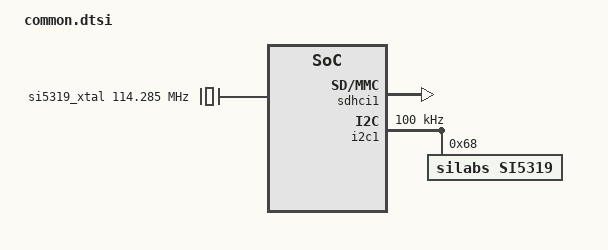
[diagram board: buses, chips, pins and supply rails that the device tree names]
/include/ "system-conf.dtsi"

// / {
// 	chosen {
// 		bootargs = "earlycon console=ttyPS0,115200 root=/dev/ram0 rw cma=256M uio_pdrv_genirq.of_id=generic-uio";
// 		stdout-path = "serial0:115200n8";
// 	};
// };

&sdhci1 {
	status = "okay";
	no-1-8-v;
	disable-wp;
};

// &watchdog0 {
// 	status = "okay";
// 	reset-on-timeout;
// 	timeout-sec = <10>;
// };

// &usb0 {
// 	status = "okay";
// };

// &dwc3_0 {
// 	status = "okay";
// 	dr_mode = "host";
// 	snps,usb3_lpm_capable;
// 	phy-names = "usb3-phy";
// 	// phys = <&lane2 PHY_TYPE_USB3 0 2 26000000>;
// 	phys = <&lane2 PHY_TYPE_USB3 0 3 26000000>;
// 	maximum-speed = "super-speed";
// };

// &usb1 {
// 	status = "okay";
// };

// &dwc3_1 {
// 	status = "okay";
// 	dr_mode = "host";
// 	snps,usb3_lpm_capable;
// 	phy-names = "usb3-phy";
// 	// phys = <&lane3 PHY_TYPE_USB3 1 3 26000000>;
// 	phys = <&lane3 PHY_TYPE_USB3 1 3 26000000>;
// 	maximum-speed = "super-speed";
// };

////////////////////////////////////////////////////////////////////////////
// system peripherals

&amba_pl {
	// si5341_xtal: si5341_xtal {
	// 	compatible = "fixed-clock";
	// 	#clock-cells = <0>;
	// 	clock-frequency = <48000000>;
	// };

	si5319_xtal: si5319_xtal {
		compatible = "fixed-clock";
		#clock-cells = <0>;
		clock-frequency = <114285000>;
	};

	// si5341_vdd_1_8: si5341_regulator@0 {
	// 	compatible = "regulator-fixed";
	// 	regulator-name = "si5341_vdd_1_8";
	// 	regulator-min-microvolt = <1800000>;
	// 	regulator-max-microvolt = <1800000>;
	// 	regulator-always-on;
	// };

	// si5341_vdd_3_3: si5341_regulator@1 {
	// 	compatible = "regulator-fixed";
	// 	regulator-name = "si5341_vdd_3_3";
	// 	regulator-min-microvolt = <3300000>;
	// 	regulator-max-microvolt = <3300000>;
	// 	regulator-always-on;
	// };
};

&i2c1 {
	clock-frequency = <100000>;

	// si5341: clock-generator@76 {
	// 	status = "okay";
	// 	reg = <0x76>;
	// 	compatible = "silabs,si5341";
	// 	#clock-cells = <2>;
	// 	#address-cells = <1>;
	// 	#size-cells = <0>;
	// 	clocks = <&si5341_xtal>;
	// 	clock-names = "xtal";

	// 	silabs,iovdd-33;
	// 	silabs,pll-m-num = <14000>; /* PLL at 14.0 GHz */
	// 	silabs,pll-m-den = <48>;
	// 	silabs,reprogram; /* Chips are not programmed, always reset */

	// 	vdd-supply = <&si5341_vdd_1_8>;
	// 	vdda-supply = <&si5341_vdd_3_3>;
	// 	vddo0-supply = <&si5341_vdd_3_3>;
	// 	vddo2-supply = <&si5341_vdd_3_3>;
	// 	vddo4-supply = <&si5341_vdd_3_3>;
	// 	vddo5-supply = <&si5341_vdd_3_3>;
	// 	vddo6-supply = <&si5341_vdd_3_3>;
	// 	vddo8-supply = <&si5341_vdd_3_3>;
	// 	vddo9-supply = <&si5341_vdd_3_3>;

	// 	out@0 {
	// 		reg = <0>;
	// 		silabs,format = <1>; /* LVDS 3v3 */
	// 		silabs,synth-master;
	// 		always-on;
	// 	};

	// 	out@2 {
	// 		reg = <2>;
	// 		silabs,format = <1>; /* LVDS 3v3 */
	// 		silabs,synth-master;
	// 		always-on;
	// 	};

	// 	out@4 {
	// 		reg = <4>;
	// 		silabs,format = <1>; /* LVDS 3v3 */
	// 		silabs,synth-master;
	// 		always-on;
	// 	};

	// 	out@5 {
	// 		reg = <5>;
	// 		silabs,format = <1>; /* LVDS 3v3 */
	// 		silabs,synth-master;
	// 		always-on;
	// 	};

	// 	out@6 {
	// 		reg = <6>;
	// 		silabs,format = <1>; /* LVDS 3v3 */
	// 		silabs,synth-master;
	// 		always-on;
	// 	};

	// 	out@8 {
	// 		reg = <8>;
	// 		silabs,format = <1>; /* LVDS 3v3 */
	// 		silabs,synth-master;
	// 		always-on;
	// 	};

	// 	out@9 {
	// 		reg = <9>;
	// 		silabs,format = <1>; /* LVDS 3v3 */
	// 		silabs,synth-master;
	// 		always-on;
	// 	};
	// };

	si5319: clock-generator@68 {
		status = "okay";
		compatible = "silabs,si5319";
		reg = <0x68>;
		#address-cells = <1>;
		#size-cells = <0>;
		#clock-cells = <1>;
		clocks = <&si5319_xtal>;
		clock-names = "xtal";

		clk0 {
			reg = <0>;
			clock-frequency = <0>;
		};
	};
};

&zzlab_env_ctrl_0 {
	compatible = "yuan,zzlab-env";

	// assigned-clocks =
	// 	<&si5341 0 0>,
	// 	<&si5341 0 2>,
	// 	<&si5341 0 4>,
	// 	<&si5341 0 5>,
	// 	<&si5341 0 6>,
	// 	<&si5341 0 8>,
	// 	<&si5341 0 9>;
	// assigned-clock-parents =
	// 	<&si5341 1 0>,
	// 	<&si5341 1 0>,
	// 	<&si5341 1 1>,
	// 	<&si5341 1 3>,
	// 	<&si5341 1 4>,
	// 	<&si5341 1 0>,
	// 	<&si5341 1 2>;
	// assigned-clock-rates =
	// 	<26000000>,
	// 	<26000000>,
	// 	<156250000>,
	// 	<18432000>,
	// 	<18432000>,
	// 	<299000000>,
	// 	<114285000>;
};
